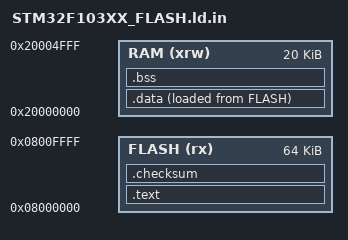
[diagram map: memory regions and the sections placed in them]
/* Configure-only template for an explicitly managed bare-metal target. */
MEMORY
{
  FLASH (rx) : ORIGIN = 0x08000000, LENGTH = 64K
  RAM (xrw) : ORIGIN = 0x20000000, LENGTH = 20K
}
_estack = ORIGIN(RAM) + LENGTH(RAM);
_Min_Heap_Size = @HEAP_SIZE@;
_Min_Stack_Size = @STACK_SIZE@;
SECTIONS
{
  .text @USE_READONLY@ : { *(.text*) *(.rodata*) } > FLASH
  .checksum : { KEEP(*(.checksum)) } > FLASH
  .data : { *(.data*) } > RAM AT > FLASH
  .bss : { *(.bss*) *(COMMON) } > RAM
}
